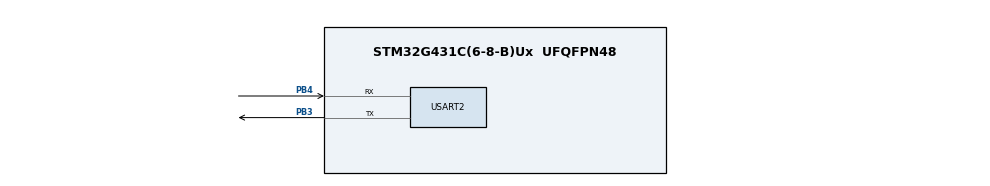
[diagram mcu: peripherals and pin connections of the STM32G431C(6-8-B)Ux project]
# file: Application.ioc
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Mcu.Family=STM32G4
Mcu.Name=STM32G431C(6-8-B)Ux
Mcu.Package=UFQFPN48
NVIC.PriorityGroup=NVIC_PRIORITYGROUP_4
NVIC.USART2_IRQn=true\:0\:0\:false\:false\:false\:true\:false\:true
PA13.Mode=Serial_Wire
PA13.Signal=SYS_JTMS-SWDIO
PA14.Mode=Serial_Wire
PA14.Signal=SYS_JTCK-SWCLK
PB3.Mode=Asynchronous
PB3.Signal=USART2_TX
PB4.Mode=Asynchronous
PB4.Signal=USART2_RX
PF0-OSC_IN.Mode=HSE-External-Oscillator
PF0-OSC_IN.Signal=RCC_OSC_IN
PF1-OSC_OUT.Mode=HSE-External-Oscillator
PF1-OSC_OUT.Signal=RCC_OSC_OUT
ProjectManager.HeapSize=0x200
ProjectManager.StackSize=0x400
ProjectManager.TargetToolchain=STM32CubeIDE
RCC.ADC12Freq_Value=170000000
RCC.AHBFreq_Value=170000000
RCC.APB1Freq_Value=170000000
RCC.APB1TimFreq_Value=170000000
RCC.APB2Freq_Value=170000000
RCC.APB2TimFreq_Value=170000000
RCC.CortexFreq_Value=170000000
RCC.EXTERNAL_CLOCK_VALUE=12288000
RCC.HCLKFreq_Value=170000000
RCC.HSE_VALUE=8000000
RCC.HSI48_VALUE=48000000
RCC.HSI_VALUE=16000000
RCC.LSE_VALUE=32768
RCC.PLLM=RCC_PLLM_DIV2
RCC.PLLN=85
RCC.PLLSourceVirtual=RCC_PLLSOURCE_HSE
RCC.SYSCLKFreq_VALUE=170000000
RCC.SYSCLKSource=RCC_SYSCLKSOURCE_PLLCLK
RCC.USBFreq_Value=170000000
RCC.VCOOutputFreq_Value=340000000
USART2.VirtualMode-Asynchronous=VM_ASYNC
VP_SYS_VS_DBSignals.Mode=DisableDeadBatterySignals
board=custom

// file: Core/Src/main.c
/* USER CODE BEGIN Header */
/**
  ******************************************************************************
  * @file           : main.c
  * @brief          : Main program body
  ******************************************************************************
  * @attention
  *
  * Copyright (c) 2024 STMicroelectronics.
  * All rights reserved.
  *
  * This software is licensed under terms that can be found in the LICENSE file
  * in the root directory of this software component.
  * If no LICENSE file comes with this software, it is provided AS-IS.
  *
  ******************************************************************************
  */
/* USER CODE END Header */
#include "main.h"

/* USER CODE BEGIN Includes */
#include "sys_command_line.h"
#include "bsp_usart.h"
/* USER CODE END Includes */

UART_HandleTypeDef huart2;

/* USER CODE BEGIN PV */
// noinit variable for firmware update...
volatile IAP_DATA_t iap_data __attribute__((section(".noinit")));
/* USER CODE END PV */

void SystemClock_Config(void);
static void MX_GPIO_Init(void);
/* USER CODE BEGIN PFP */
HAL_StatusTypeDef APP_UARTxInit(UART_HandleTypeDef *huart);
/* USER CODE END PFP */

/* USER CODE BEGIN 0 */
#if !defined(DEBUG)
void Disable_SWD_GPIO(void)
{
  GPIO_InitTypeDef GPIO_InitStruct = {0};
  __HAL_RCC_GPIOA_CLK_ENABLE();

  GPIO_InitStruct.Pin = GPIO_PIN_13 | GPIO_PIN_14;
  GPIO_InitStruct.Mode = GPIO_MODE_ANALOG;
  GPIO_InitStruct.Pull = GPIO_NOPULL;
  HAL_GPIO_Init(GPIOA, &GPIO_InitStruct);
  return;
}

uint32_t GetRDPLevel(void)
{
  FLASH_OBProgramInitTypeDef OBInit;
  HAL_FLASHEx_OBGetConfig(&OBInit);
  return OBInit.RDPLevel;
}

void EnableRDP(void)
{
  FLASH_OBProgramInitTypeDef OBInit;

  // 解鎖 Flash 控制寄存器
  HAL_FLASH_Unlock();
  HAL_FLASH_OB_Unlock();

  // 獲取當前的選項位配置
  HAL_FLASHEx_OBGetConfig(&OBInit);

  // 設置 RDP 等級為 Level 1
  OBInit.OptionType = OPTIONBYTE_RDP;
  OBInit.RDPLevel = OB_RDP_LEVEL_1;

  // 設置新的選項位配置
  if ( HAL_FLASHEx_OBProgram(&OBInit) != HAL_OK )
  {
	// 處理錯誤
    ;
  }

  // 啟動選項位加載
  HAL_FLASH_OB_Launch();

  // 鎖定 Flash 控制寄存器
  HAL_FLASH_OB_Lock();
  HAL_FLASH_Lock();
}
#endif
/* USER CODE END 0 */

int main(void)
{
  /* USER CODE BEGIN 1 */
  // Restore global interruption after switching...
  __enable_irq();
  /* USER CODE END 1 */

  /* MCU Configuration--------------------------------------------------------*/

  /* Reset of all peripherals, Initializes the Flash interface and the Systick. */
  HAL_Init();

  /* Configure the system clock */
  SystemClock_Config();

  /* Initialize all configured peripherals */
  MX_GPIO_Init();
  MX_USART2_UART_Init();
  /* USER CODE BEGIN 2 */

#if !defined(DEBUG)
  Disable_SWD_GPIO();
  if ( GetRDPLevel() == OB_RDP_LEVEL_0 )
  {
  	EnableRDP();
  }
#endif
  /*
   * IAP Software update completed...
   */
  uint16_t crc16 = (uint16_t) ~(iap_data.EntryIAP);
  if ( iap_data.EntryIAP == IAP_ENTRY_CODE && crc16 == IAP_NOT_ENTRY_CODE )
  {
	// .noinit ram initialize...
    iap_data.EntryIAP	= 0x0000;
	iap_data.crc16		= 0x0000;

	/*
	 *  Update EEPROM parameters (for new
	 *	software updates, EEPROM parameters
	 *	must also be updated)
	 */
	// EEPROM_update();
  }
  assert_param( APP_UARTxInit(&huart2) == HAL_OK );
  cli_init(115200);
  /* USER CODE END 2 */

  /* Infinite loop */
  /* USER CODE BEGIN WHILE */
  while (1)
  {
	CLI_RUN();
    /* USER CODE END WHILE */

  }
}

void SystemClock_Config(void)
{
  LL_FLASH_SetLatency(LL_FLASH_LATENCY_4);
  while(LL_FLASH_GetLatency() != LL_FLASH_LATENCY_4)
  {
  }
  LL_PWR_EnableRange1BoostMode();
  LL_RCC_HSE_Enable();
   /* Wait till HSE is ready */
  while(LL_RCC_HSE_IsReady() != 1)
  {
  }

  LL_RCC_PLL_ConfigDomain_SYS(LL_RCC_PLLSOURCE_HSE, LL_RCC_PLLM_DIV_2, 85, LL_RCC_PLLR_DIV_2);
  LL_RCC_PLL_EnableDomain_SYS();
  LL_RCC_PLL_Enable();
   /* Wait till PLL is ready */
  while(LL_RCC_PLL_IsReady() != 1)
  {
  }

  LL_RCC_SetSysClkSource(LL_RCC_SYS_CLKSOURCE_PLL);
  LL_RCC_SetAHBPrescaler(LL_RCC_SYSCLK_DIV_2);
   /* Wait till System clock is ready */
  while(LL_RCC_GetSysClkSource() != LL_RCC_SYS_CLKSOURCE_STATUS_PLL)
  {
  }

  /* Insure 1us transition state at intermediate medium speed clock*/
  for (__IO uint32_t i = (170 >> 1); i !=0; i--);

  /* Set AHB prescaler*/
  LL_RCC_SetAHBPrescaler(LL_RCC_SYSCLK_DIV_1);
  LL_RCC_SetAPB1Prescaler(LL_RCC_APB1_DIV_1);
  LL_RCC_SetAPB2Prescaler(LL_RCC_APB2_DIV_1);
  LL_SetSystemCoreClock(170000000);

   /* Update the time base */
  if (HAL_InitTick (TICK_INT_PRIORITY) != HAL_OK)
  {
    Error_Handler();
  }
}

void MX_USART2_UART_Init(void)
{

  huart2.Instance = USART2;
  huart2.Init.BaudRate = 115200;
  huart2.Init.WordLength = UART_WORDLENGTH_8B;
  huart2.Init.StopBits = UART_STOPBITS_1;
  huart2.Init.Parity = UART_PARITY_NONE;
  huart2.Init.Mode = UART_MODE_TX_RX;
  huart2.Init.HwFlowCtl = UART_HWCONTROL_NONE;
  huart2.Init.OverSampling = UART_OVERSAMPLING_16;
  huart2.Init.OneBitSampling = UART_ONE_BIT_SAMPLE_DISABLE;
  huart2.Init.ClockPrescaler = UART_PRESCALER_DIV1;
  huart2.AdvancedInit.AdvFeatureInit = UART_ADVFEATURE_NO_INIT;
  if (HAL_UART_Init(&huart2) != HAL_OK)
  {
    Error_Handler();
  }
  if (HAL_UARTEx_SetTxFifoThreshold(&huart2, UART_TXFIFO_THRESHOLD_1_8) != HAL_OK)
  {
    Error_Handler();
  }
  if (HAL_UARTEx_SetRxFifoThreshold(&huart2, UART_RXFIFO_THRESHOLD_1_8) != HAL_OK)
  {
    Error_Handler();
  }
  if (HAL_UARTEx_DisableFifoMode(&huart2) != HAL_OK)
  {
    Error_Handler();
  }

}

static void MX_GPIO_Init(void)
{
  GPIO_InitTypeDef GPIO_InitStruct = {0};

  /* GPIO Ports Clock Enable */
  __HAL_RCC_GPIOC_CLK_ENABLE();
  __HAL_RCC_GPIOF_CLK_ENABLE();
  __HAL_RCC_GPIOG_CLK_ENABLE();
  __HAL_RCC_GPIOA_CLK_ENABLE();
  __HAL_RCC_GPIOB_CLK_ENABLE();

  /*Configure GPIO pins : PC13 PC14 PC15 PC4
                           PC6 PC10 PC11 */
  GPIO_InitStruct.Pin = GPIO_PIN_13|GPIO_PIN_14|GPIO_PIN_15|GPIO_PIN_4
                          |GPIO_PIN_6|GPIO_PIN_10|GPIO_PIN_11;
  GPIO_InitStruct.Mode = GPIO_MODE_ANALOG;
  GPIO_InitStruct.Pull = GPIO_NOPULL;
  HAL_GPIO_Init(GPIOC, &GPIO_InitStruct);

  /*Configure GPIO pin : PG10 */
  GPIO_InitStruct.Pin = GPIO_PIN_10;
  GPIO_InitStruct.Mode = GPIO_MODE_ANALOG;
  GPIO_InitStruct.Pull = GPIO_NOPULL;
  HAL_GPIO_Init(GPIOG, &GPIO_InitStruct);

  /*Configure GPIO pins : PA0 PA1 PA2 PA3
                           PA4 PA5 PA6 PA7
                           PA8 PA9 PA10 PA11
                           PA12 PA15 */
  GPIO_InitStruct.Pin = GPIO_PIN_0|GPIO_PIN_1|GPIO_PIN_2|GPIO_PIN_3
                          |GPIO_PIN_4|GPIO_PIN_5|GPIO_PIN_6|GPIO_PIN_7
                          |GPIO_PIN_8|GPIO_PIN_9|GPIO_PIN_10|GPIO_PIN_11
                          |GPIO_PIN_12|GPIO_PIN_15;
  GPIO_InitStruct.Mode = GPIO_MODE_ANALOG;
  GPIO_InitStruct.Pull = GPIO_NOPULL;
  HAL_GPIO_Init(GPIOA, &GPIO_InitStruct);

  /*Configure GPIO pins : PB0 PB1 PB2 PB10
                           PB11 PB12 PB13 PB14
                           PB15 PB5 PB6 PB7
                           PB8 PB9 */
  GPIO_InitStruct.Pin = GPIO_PIN_0|GPIO_PIN_1|GPIO_PIN_2|GPIO_PIN_10
                          |GPIO_PIN_11|GPIO_PIN_12|GPIO_PIN_13|GPIO_PIN_14
                          |GPIO_PIN_15|GPIO_PIN_5|GPIO_PIN_6|GPIO_PIN_7
                          |GPIO_PIN_8|GPIO_PIN_9;
  GPIO_InitStruct.Mode = GPIO_MODE_ANALOG;
  GPIO_InitStruct.Pull = GPIO_NOPULL;
  HAL_GPIO_Init(GPIOB, &GPIO_InitStruct);

}

/* USER CODE BEGIN 4 */
HAL_StatusTypeDef APP_UARTxInit(UART_HandleTypeDef *huart)
{
  HAL_StatusTypeDef status = HAL_OK;
#if 1
  setvbuf(stdout, NULL, _IONBF, 0);  // Set printf to have no buffering and print directly.
  /* Enable the UART Error Interrupt: (Frame error, noise error, overrun error) */
  ATOMIC_SET_BIT(huart->Instance->CR3, USART_CR3_EIE);
  ATOMIC_SET_BIT(huart->Instance->CR1, USART_CR1_RXNEIE_RXFNEIE);
#else
  status = HAL_UART_Receive_IT(huart, &uart_rx_buffer, 1);
#endif
  return status;
}
/* USER CODE END 4 */

void Error_Handler(void)
{
  __disable_irq();
  while (1)
  {
  }
}

#ifdef  USE_FULL_ASSERT
/**
  * @brief  Reports the name of the source file and the source line number
  *         where the assert_param error has occurred.
  * @param  file: pointer to the source file name
  * @param  line: assert_param error line source number
  * @retval None
  */
void assert_failed(uint8_t *file, uint32_t line)
{
  /* USER CODE BEGIN 6 */
  /* User can add his own implementation to report the file name and line number,
     ex: printf("Wrong parameters value: file %s on line %d\r\n", file, line) */
  printf("Wrong parameters value: file %s on line %ld\r\n", file, line);
  /* USER CODE END 6 */
}
#endif /* USE_FULL_ASSERT */
